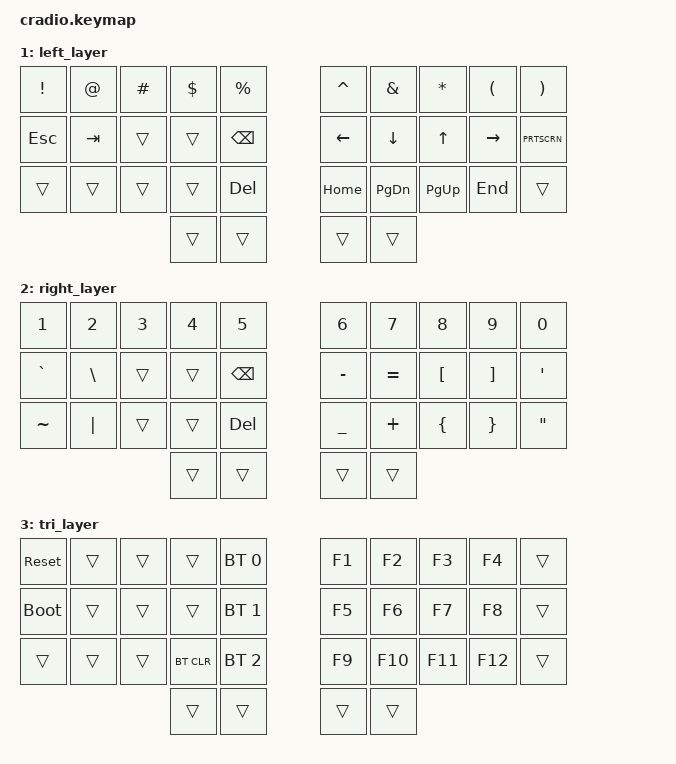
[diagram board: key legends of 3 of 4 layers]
// Copyright (c) 2022 The ZMK Contributors
// SPDX-License-Identifier: MIT

#include <behaviors.dtsi>
#include <dt-bindings/zmk/keys.h>
#include <dt-bindings/zmk/bt.h>

// Home row mods macro
#define HRML(k1,k2,k3,k4) &ht LSHFT k1  &ht LALT k2  &ht LCTRL k3  &ht LGUI k4
#define HRMR(k1,k2,k3,k4) &ht RGUI k1  &ht RCTRL k2  &ht RALT k3  &ht RSHFT k4

/ {
    behaviors {
        ht: hold_tap {
            compatible = "zmk,behavior-hold-tap";
            #binding-cells = <2>;
            flavor = "tap-preferred";
            tapping-term-ms = <220>;
            quick-tap-ms = <150>;
            require-prior-idle-ms = <100>;
            bindings = <&kp>, <&kp>;
        };
    };

    conditional_layers {
        compatible = "zmk,conditional-layers";
        tri_layer {
            if-layers = <1 2>;
            then-layer = <3>;
        };
    };

    keymap {
        compatible = "zmk,keymap";
        default_layer {
            bindings = <
        //╭──────────┬──────────┬──────────┬──────────┬──────────╮   ╭──────────┬──────────┬──────────┬──────────┬──────────╮
        //│  Q       │  W       │  E       │  R       │  T       │   │  Y       │  U       │  I       │  O       │  P       │
            &kp Q      &kp W      &kp E      &kp R      &kp T          &kp Y      &kp U      &kp I      &kp O      &kp P
        //├──────────┼──────────┼──────────┼──────────┼──────────┤   ├──────────┼──────────┼──────────┼──────────┼──────────┤
        //│  A       │  S       │  D       │  F       │  G       │   │  H       │  J       │  K       │  L       │ ' "      │
            HRML(A,        S,         D,         F)     &kp G          &kp H      HRMR(J,        K,         L,        SEMI)
        //├──────────┼──────────┼──────────┼──────────┼──────────┤   ├──────────┼──────────┼──────────┼──────────┼──────────┤
        //│  Z       │  X       │  C       │  V       │  B       │   │  N       │  M       │ , <      │ . >      │ / ?      │
            &kp Z      &kp X      &kp C      &kp V      &kp B          &kp N      &kp M      &kp COMMA  &kp DOT    &kp FSLH
        //╰──────────┴──────────┴──────────┼──────────┼──────────┤   ├──────────┼──────────┼──────────┴──────────┴──────────╯
                                            &mo 1    &kp SPACE     &kp ENTER  &mo 2 
        //                                 ╰──────────┴──────────╯   ╰──────────┴──────────╯
            >;
        };

        left_layer {
            bindings = <
        //╭──────────┬──────────┬──────────┬──────────┬──────────╮   ╭──────────┬──────────┬──────────┬──────────┬──────────╮
        //│ INSERT   │  1       │  2       │  3       │          │   │ HOME     │ PAGE DN  │ PAGE UP  │ END      │  :       │
            &kp EXCL    &kp AT     &kp HASH  &kp DLLR   &kp PRCNT      &kp CARET  &kp AMPS  &kp ASTRK  &kp LPAR   &kp RPAR
        //├──────────┼──────────┼──────────┼──────────┼──────────┤   ├──────────┼──────────┼──────────┼──────────┼──────────┤
        //│ DELETE   │  4       │  5       │  6       │          │   │ LEFT     │ DOWN     │ UP       │ RIGHT    │  ;       │
            &kp ESC     &kp TAB      &trans      &trans  &kp BSPC      &kp LEFT   &kp DOWN   &kp UP   &kp RIGHT   &kp PRTSCRN
        //├──────────┼──────────┼──────────┼──────────┼──────────┤   ├──────────┼──────────┼──────────┼──────────┼──────────┤
        //│ CAPS     │  7       │  8       │  9       │  0       │   │          │          │          │          │   :      │
           &trans   &trans     &trans     &trans     &kp DEL         &kp HOME   &kp PG_DN  &kp PG_UP  &kp END    &trans
        //╰──────────┴──────────┴──────────┼──────────┼──────────┤   ├──────────┼──────────┼──────────┴──────────┴──────────╯
                                             &trans     &trans         &trans     &trans
        //                                 ╰──────────┴──────────╯   ╰──────────┴──────────╯
            >;
        };

        right_layer {
            bindings = <
        //╭──────────┬──────────┬──────────┬──────────┬──────────╮   ╭──────────┬──────────┬──────────┬──────────┬──────────╮
        //│          │  [       │  {       │  }       │          │   │  ^       │  (       │  )       │  ]       │  ~       │
            &kp N1     &kp N2     &kp N3     &kp N4    &kp N5         &kp N6      &kp N7    &kp N8     &kp N9      &kp N0
        //├──────────┼──────────┼──────────┼──────────┼──────────┤   ├──────────┼──────────┼──────────┼──────────┼──────────┤
        //│  !       │  @       │  #       │  $       │  %       │   │  *       │  -       │  =       │  \       │  `       │
            &kp GRAVE    &kp BSLH   &trans     &trans     &kp BSPC        &kp MINUS  &kp EQUAL   &kp LBKT   &kp RBKT   &kp SQT
        //├──────────┼──────────┼──────────┼──────────┼──────────┤   ├──────────┼──────────┼──────────┼──────────┼──────────┤
        //│          │          │          │          │          │   │  &       │  _       │  +       │  │       │          │
            &kp TILDE     &kp PIPE     &trans     &trans     &kp DEL      &kp UNDER   &kp PLUS  &kp LBRC   &kp RBRC   &kp DQT
        //╰──────────┴──────────┴──────────┼──────────┼──────────┤   ├──────────┼──────────┼──────────┴──────────┴──────────╯
                                             &trans     &trans         &trans     &trans
        //                                 ╰──────────┴──────────╯   ╰──────────┴──────────╯
            >;
        };

        tri_layer {
            bindings = <
        //╭──────────┬──────────┬──────────┬──────────┬──────────╮   ╭──────────┬──────────┬──────────┬──────────┬──────────╮
        //│ RESET    │          │          │          │PROFILE 0 │   │          │          │          │          │          │
           &sys_reset  &trans     &trans     &trans    &bt BT_SEL 0    &kp F1     &kp F2     &kp F3     &kp F4    &trans
        //├──────────┼──────────┼──────────┼──────────┼──────────┤   ├──────────┼──────────┼──────────┼──────────┼──────────┤
        //│BOOTLOADER│          │          │          │PROFILE 1 │   │          │          │          │          │          │
          &bootloader  &trans     &trans     &trans    &bt BT_SEL 1    &kp F5     &kp F6     &kp F7     &kp F8    &trans
        //├──────────┼──────────┼──────────┼──────────┼──────────┤   ├──────────┼──────────┼──────────┼──────────┼──────────┤
        //│          │          │          │ CLEAR BT │PROFILE 2 │   │          │          │          │          │          │
            &trans     &trans     &trans    &bt BT_CLR &bt BT_SEL 2    &kp F9     &kp F10     &kp F11     &kp F12     &trans
        //╰──────────┴──────────┴──────────┼──────────┼──────────┤   ├──────────┼──────────┼──────────┴──────────┴──────────╯
                                             &trans     &trans         &trans     &trans
        //                                 ╰──────────┴──────────╯   ╰──────────┴──────────╯
            >;
        };
    };
};
